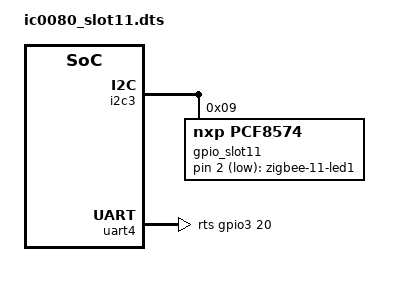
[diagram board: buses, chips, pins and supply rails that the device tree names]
/dts-v1/;


/plugin/;

/ {
	fragment@0 {
		target = <&i2c3>;
		__overlay__ {
			#address-cells = <1>;
			#size-cells = <0>;
			gpio_slot11: pca9501@9 {
				compatible = "nxp,pcf8574";
				gpio-controller;
				#gpio-cells = <2>;
				reg = <9>;
				lines-initial-states = <0xfd>;
				gpio-line-names = "zigbee_11_btn",
				                  "zigbee_11_bootn",
				                  "zigbee_11_led1",
				                  "",
				                  "zigbee_11_pti_frame",
				                  "zigbee_11_pti_data",
				                  "zigbee_11_resetn", "";
				reset_n-hog {
					gpio-hog;
					gpios = <6 1>;
					output-low;
					line-name = "reset";
				};
				boot_n-hog {
					gpio-hog;
					gpios = <1 1>;
					output-low;
					line-name = "boot";
				};
			};
		};
	};

	fragment@3 {
		
		target = <&uart4>;
		__overlay__ {
			status = "okay";
			pinctrl-names = "default";
			pinctrl-0 = <&pinctrl_uart4>, <&pinctrl_uart4_ctrl>;
			rts-gpios = <&gpio3 20 0>;
		};

	};

	fragment@4 {
		target-path = "/";
		__overlay__ {
			loraleds {
				compatible = "gpio-leds";
				zigbee-led@0 {
					label = "zigbee-11-led1";
					gpios = <&gpio_slot11 2 1>;
					default-state = "off";
					linux,default-trigger = "none";
				};
			};
		};
	};
};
